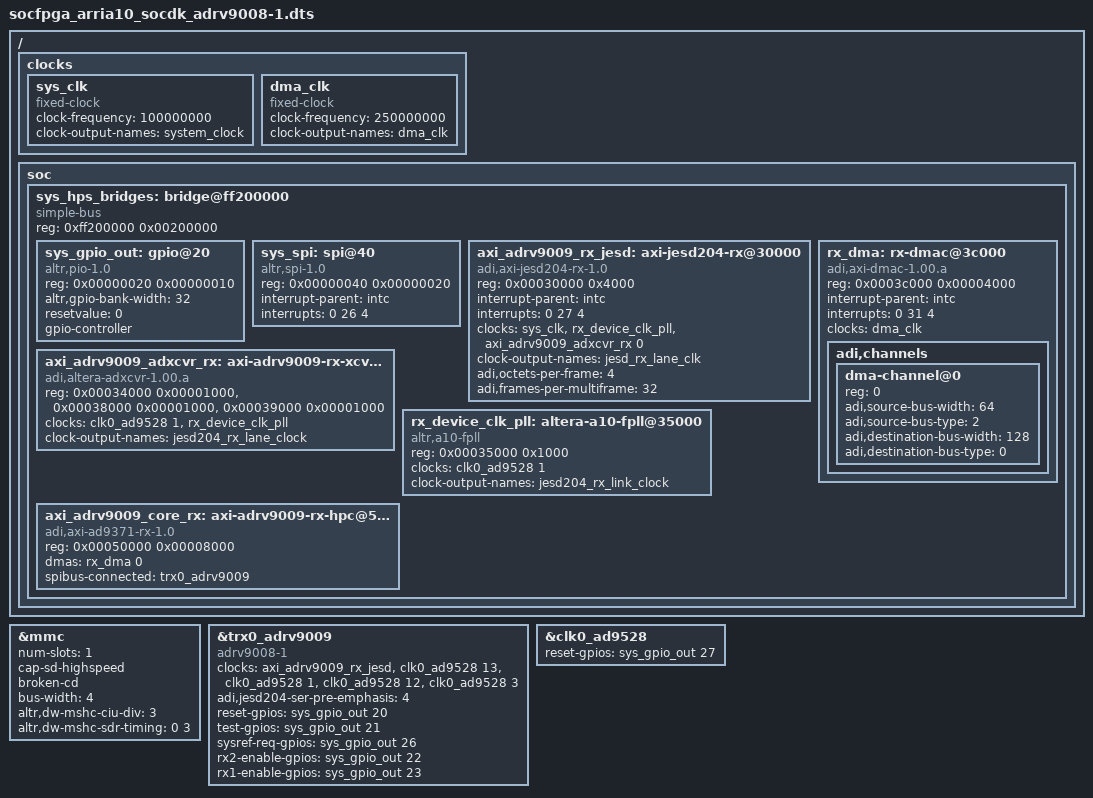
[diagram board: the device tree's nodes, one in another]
/dts-v1/;
#include "socfpga_arria10_socdk.dtsi"
#include <dt-bindings/iio/frequency/ad9528.h>

&mmc {
	status = "okay";
	num-slots = <1>;
	cap-sd-highspeed;
	broken-cd;
	bus-width = <4>;
	altr,dw-mshc-ciu-div = <3>;
	altr,dw-mshc-sdr-timing = <0 3>;
};

/ {
	clocks {
		sys_clk: sys_clk {
			#clock-cells = <0>;
			compatible = "fixed-clock";
			clock-frequency = <100000000>;
			clock-output-names = "system_clock";
		};

		dma_clk: dma_clk {
			#clock-cells = <0x0>;
			compatible = "fixed-clock";
			clock-frequency = <250000000>;
			clock-output-names = "dma_clk";
		};
	};

	soc {
		sys_hps_bridges: bridge@ff200000 {
			compatible = "simple-bus";
			reg = <0xff200000 0x00200000>;
			#address-cells = <1>;
			#size-cells = <1>;
			ranges = <0x00000000 0xff200000 0x00200000>;

			sys_gpio_out: gpio@20 {
				compatible = "altr,pio-1.0";
				reg = <0x00000020 0x00000010>;
				altr,gpio-bank-width = <32>;
				resetvalue = <0>;
				#gpio-cells = <2>;
				gpio-controller;
			};

			sys_spi: spi@40 {
				compatible = "altr,spi-1.0";
				reg = <0x00000040 0x00000020>;
				interrupt-parent = <&intc>;
				interrupts = <0 26 4>;
				#address-cells = <0x1>;
				#size-cells = <0x0>;
			};

			axi_adrv9009_rx_jesd: axi-jesd204-rx@30000 {
				compatible = "adi,axi-jesd204-rx-1.0";
				reg = <0x00030000 0x4000>;

				interrupt-parent = <&intc>;
				interrupts = <0 27 4>;

				clocks = <&sys_clk>, <&rx_device_clk_pll>, <&axi_adrv9009_adxcvr_rx 0>;
				clock-names = "s_axi_aclk", "device_clk", "lane_clk";

				#clock-cells = <0>;
				clock-output-names = "jesd_rx_lane_clk";

				adi,octets-per-frame = <4>;
				adi,frames-per-multiframe = <32>;
			};

			axi_adrv9009_adxcvr_rx: axi-adrv9009-rx-xcvr@34000 {
				compatible = "adi,altera-adxcvr-1.00.a";
				reg = <0x00034000 0x00001000>,
					<0x00038000 0x00001000>,
					<0x00039000 0x00001000>;
				reg-names = "adxcvr", "adxcfg-0", "adxcfg-1";

				clocks = <&clk0_ad9528 1>, <&rx_device_clk_pll>;
				clock-names = "ref", "link";

				#clock-cells = <0>;
				clock-output-names = "jesd204_rx_lane_clock";
			};

			rx_device_clk_pll: altera-a10-fpll@35000 {
				compatible = "altr,a10-fpll";
				reg = <0x00035000 0x1000>;
				clocks = <&clk0_ad9528 1>;

				#clock-cells = <0>;
				clock-output-names = "jesd204_rx_link_clock";
			};

			rx_dma: rx-dmac@3c000 {
				compatible = "adi,axi-dmac-1.00.a";
				reg = <0x0003c000 0x00004000>;
				interrupt-parent = <&intc>;
				interrupts = <0 31 4>;
				#dma-cells = <1>;
				clocks = <&dma_clk>;

				adi,channels {
					#size-cells = <0>;
					#address-cells = <1>;

					dma-channel@0 {
						reg = <0>;
						adi,source-bus-width = <64>;
						adi,source-bus-type = <2>;
						adi,destination-bus-width = <128>;
						adi,destination-bus-type = <0>;
					};
				};
			};

			axi_adrv9009_core_rx: axi-adrv9009-rx-hpc@50000 {
				compatible = "adi,axi-ad9371-rx-1.0";
				reg = <0x00050000 0x00008000>;
				dmas = <&rx_dma 0>;
				dma-names = "rx";
				spibus-connected = <&trx0_adrv9009>;
			};
		};
	};
};

#define fmc_spi sys_spi

#include "adi-adrv9009.dtsi"

&trx0_adrv9009 {
	compatible = "adrv9008-1";

	clocks = <&axi_adrv9009_rx_jesd>, <&clk0_ad9528 13>,
		<&clk0_ad9528 1>, <&clk0_ad9528 12>, <&clk0_ad9528 3>;
	clock-names = "jesd_rx_clk", "dev_clk", "fmc_clk", "sysref_dev_clk",
		"sysref_fmc_clk";

	adi,jesd204-ser-pre-emphasis = <4>;
	reset-gpios = <&sys_gpio_out 20 0>;
	test-gpios = <&sys_gpio_out 21 0>;
	sysref-req-gpios = <&sys_gpio_out 26 0>;
	rx2-enable-gpios = <&sys_gpio_out 22 0>;
	rx1-enable-gpios = <&sys_gpio_out 23 0>;
};

&clk0_ad9528 {
	reset-gpios = <&sys_gpio_out 27 0>;
};
